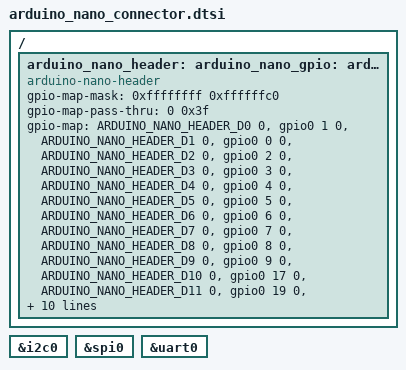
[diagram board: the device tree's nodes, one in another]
/*
 * SPDX-FileCopyrightText: Copyright (c) 2023-2026 TiaC Systems
 * SPDX-License-Identifier: Apache-2.0
 */

#include <zephyr/dt-bindings/gpio/arduino-nano-header.h>

/ {
	arduino_nano_header: arduino-nano-connector {
		compatible = "arduino-nano-header";
		#gpio-cells = <2>;
		gpio-map-mask = <0xffffffff 0xffffffc0>;
		gpio-map-pass-thru = <0 0x3f>;
		gpio-map = <ARDUINO_NANO_HEADER_D0 0 &gpio0 1 0>,	/* GP1/PWM1 / UART-RX */
			   <ARDUINO_NANO_HEADER_D1 0 &gpio0 0 0>,	/* GP0/PWM0 / UART-TX */
			   <ARDUINO_NANO_HEADER_D2 0 &gpio0 2 0>,	/* GP2/PWM2 */
			   <ARDUINO_NANO_HEADER_D3 0 &gpio0 3 0>,	/* GP3/PWM3 */
			   <ARDUINO_NANO_HEADER_D4 0 &gpio0 4 0>,	/* GP4/PWM4 */
			   <ARDUINO_NANO_HEADER_D5 0 &gpio0 5 0>,	/* GP5/PWM5 */
			   <ARDUINO_NANO_HEADER_D6 0 &gpio0 6 0>,	/* GP6/PWM6 */
			   <ARDUINO_NANO_HEADER_D7 0 &gpio0 7 0>,	/* GP7/PWM7 */
			   <ARDUINO_NANO_HEADER_D8 0 &gpio0 8 0>,	/* GP8/PWM8 */
			   <ARDUINO_NANO_HEADER_D9 0 &gpio0 9 0>,	/* GP9/PWM9 */
			   <ARDUINO_NANO_HEADER_D10 0 &gpio0 17 0>,	/* GP17/PWM1 / SPI-CSn */
			   <ARDUINO_NANO_HEADER_D11 0 &gpio0 19 0>,	/* GP19/PWM3 / SPI-COPI */
			   <ARDUINO_NANO_HEADER_D12 0 &gpio0 16 0>,	/* GP16/PWM0 / SPI-CIPO */
			   <ARDUINO_NANO_HEADER_D13 0 &gpio0 18 0>,	/* GP18/PWM2 / SPI-SCK */
			   <ARDUINO_NANO_HEADER_A0 0 &gpio0 26 0>,	/* GP26/PWM10 / A0 */
			   <ARDUINO_NANO_HEADER_A1 0 &gpio0 27 0>,	/* GP27/PWM11 / A1 */
			   <ARDUINO_NANO_HEADER_A2 0 &gpio0 28 0>,	/* GP28/PWM12 / A2 */
			   <ARDUINO_NANO_HEADER_A3 0 &gpio0 29 0>,	/* GP29/PWM13 / A3 */
			   <ARDUINO_NANO_HEADER_D18 0 &gpio0 12 0>,	/* GP12/PWM12 / I2C-SDA */
			   <ARDUINO_NANO_HEADER_D19 0 &gpio0 13 0>,	/* GP13/PWM13 / I2C-SCL */
			   <ARDUINO_NANO_HEADER_A6 0 &gpio0 14 0>,	/* GP14/PWM14 / (A6) */
			   <ARDUINO_NANO_HEADER_A7 0 &gpio0 15 0>;	/* GP15/PWM15 / (A7) */
	};
};

arduino_nano_i2c: &i2c0 {};
arduino_nano_spi: &spi0 {};
arduino_nano_serial: &uart0 {};
arduino_nano_gpio: &arduino_nano_header {};
